AUTOSAR XML (schema 4-3-0)
package /RoutineControl
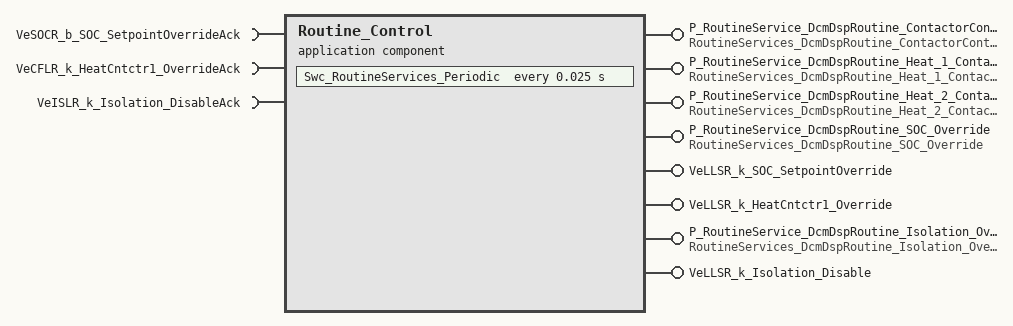
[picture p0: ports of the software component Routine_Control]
  application sw component type Routine_Control
    5 x provide port:
      P_RoutineService_DcmDspRoutine_ContactorControl: provided-interface=RoutineServices_DcmDspRoutine_ContactorControl
      P_RoutineService_DcmDspRoutine_Heat_1_ContactorControl: provided-interface=RoutineServices_DcmDspRoutine_Heat_1_ContactorControl
      P_RoutineService_DcmDspRoutine_Heat_2_ContactorControl: provided-interface=RoutineServices_DcmDspRoutine_Heat_2_ContactorControl
      P_RoutineService_DcmDspRoutine_SOC_Override: provided-interface=RoutineServices_DcmDspRoutine_SOC_Override
      VeLLSR_k_SOC_SetpointOverride: provided-interface=VeLLSR_k_SOC_SetpointOverride
    require port VeSOCR_b_SOC_SetpointOverrideAck: required-interface=VeSOCR_b_SOC_SetpointOverrideAck
    provide port VeLLSR_k_HeatCntctr1_Override: provided-interface=VeLLSR_k_HeatCntctr1_Override
    require port VeCFLR_k_HeatCntctr1_OverrideAck: required-interface=VeCFLR_k_HeatCntctr1_OverrideAck
    provide port P_RoutineService_DcmDspRoutine_Isolation_Override: provided-interface=RoutineServices_DcmDspRoutine_Isolation_Override
    provide port VeLLSR_k_Isolation_Disable: provided-interface=VeLLSR_k_Isolation_Disable
    require port VeISLR_k_Isolation_DisableAck: required-interface=VeISLR_k_Isolation_DisableAck
    behavior IB_Routine_Control: data-type-mapping=[SOCR_CodeDataTypeMappingsSet, THMR_CodeDataTypeMappingsSet, ISLR_CodeDataTypeMappingsSet, CFLR_CodeDataTypeMappingsSet]
      5 x operation invoked event:
        OIE_RoutineServices_DcmDspRoutine_ContactorControl_Start: start-on-event=Swc_RoutineServices_DcmDspRoutine_ContactorControl_Start, operation=P_RoutineService_DcmDspRoutine_ContactorControl.Start
        OIE_RoutineServices_DcmDspRoutine_ContactorControl_Stop: start-on-event=Swc_RoutineServices_DcmDspRoutine_ContactorControl_Stop, operation=P_RoutineService_DcmDspRoutine_ContactorControl.Stop
        OperationInvokedEvent_0: start-on-event=Swc_RoutineServices_DcmDspRoutine_Heat_1_ContactorControl, operation=P_RoutineService_DcmDspRoutine_Heat_1_ContactorControl.Start
        OperationInvokedEvent_1: start-on-event=Swc_RoutineServices_DcmDspRoutine_Heat_2_ContactorControl, operation=P_RoutineService_DcmDspRoutine_Heat_2_ContactorControl.Start
        OperationInvokedEvent_2: start-on-event=Swc_RoutineServices_DcmDspRoutine_SOC_Override, operation=P_RoutineService_DcmDspRoutine_SOC_Override.Start
      timing event TimingEvent_0: start-on-event=Swc_RoutineServices_Periodic, period=0.025
      operation invoked event OperationInvokedEvent_3: start-on-event=Swc_RoutineServices_DcmDspRoutine_Isolation_Override, operation=P_RoutineService_DcmDspRoutine_Isolation_Override.Start
      7 x runnable:
        Swc_RoutineServices_DcmDspRoutine_ContactorControl_Start: symbol=Swc_RoutineServices_DcmDspRoutine_ContactorControl_Start_func
        Swc_RoutineServices_DcmDspRoutine_ContactorControl_Stop: symbol=Swc_RoutineServices_DcmDspRoutine_ContactorControl_Stop_func
        Swc_RoutineServices_DcmDspRoutine_Heat_1_ContactorControl: symbol=Swc_RoutineServices_DcmDspRoutine_Heat_1_ContactorControl_Func
        Swc_RoutineServices_DcmDspRoutine_Heat_2_ContactorControl: symbol=Swc_RoutineServices_DcmDspRoutine_Heat_2_ContactorControl_Func
        Swc_RoutineServices_DcmDspRoutine_SOC_Override: symbol=Swc_RoutineServices_DcmDspRoutine_SOC_Override_Func
        Swc_RoutineServices_Periodic: symbol=Swc_RoutineServices_Periodic_Runnable
          data-read-access:
            access DRA_VeSOCR_b_SOC_SetpointOverrideAck_0: accessed-variable=VeSOCR_b_SOC_SetpointOverrideAck.VeSOCR_b_SOC_SetpointOverrideAck
            access DRA_VeISLR_k_Isolation_DisableAck_0: accessed-variable=VeISLR_k_Isolation_DisableAck.VeISLR_k_Isolation_DisableAck
            access DRA_VeCFLR_k_HeatCntctr1_OverrideAck_0: accessed-variable=VeCFLR_k_HeatCntctr1_OverrideAck.VeCFLR_k_HeatCntctr1_OverrideAck
          data-write-access:
            access DWA_VeLLSR_k_SOC_SetpointOverride_0: accessed-variable=VeLLSR_k_SOC_SetpointOverride.VeLLSR_k_SOC_SetpointOverride
            access DWA_VeLLSR_k_Isolation_Disable_0: accessed-variable=VeLLSR_k_Isolation_Disable.VeLLSR_k_Isolation_Disable
            access DWA_VeLLSR_k_HeatCntctr1_Override_0: accessed-variable=VeLLSR_k_HeatCntctr1_Override.VeLLSR_k_HeatCntctr1_Override
        Swc_RoutineServices_DcmDspRoutine_Isolation_Override: symbol=Swc_RoutineServices_DcmDspRoutine_Isolation_Override_Func
